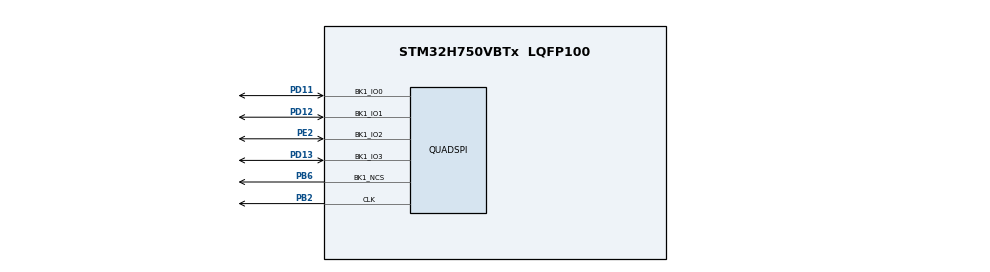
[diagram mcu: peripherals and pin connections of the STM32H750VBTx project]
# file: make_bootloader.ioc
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CORTEX_M7.default_mode_Activation=1
Mcu.Family=STM32H7
Mcu.Name=STM32H750VBTx
Mcu.Package=LQFP100
NVIC.PriorityGroup=NVIC_PRIORITYGROUP_4
PB2.GPIO_Speed=GPIO_SPEED_FREQ_VERY_HIGH
PB2.Mode=Single Bank 1
PB2.Signal=QUADSPI_CLK
PB6.GPIO_Speed=GPIO_SPEED_FREQ_VERY_HIGH
PB6.Mode=Single Bank 1
PB6.Signal=QUADSPI_BK1_NCS
PD11.GPIO_Speed=GPIO_SPEED_FREQ_VERY_HIGH
PD11.Mode=Single Bank 1
PD11.Signal=QUADSPI_BK1_IO0
PD12.GPIO_Speed=GPIO_SPEED_FREQ_VERY_HIGH
PD12.Mode=Single Bank 1
PD12.Signal=QUADSPI_BK1_IO1
PD13.GPIO_Speed=GPIO_SPEED_FREQ_VERY_HIGH
PD13.Mode=Single Bank 1
PD13.Signal=QUADSPI_BK1_IO3
PE2.GPIO_Speed=GPIO_SPEED_FREQ_VERY_HIGH
PE2.Mode=Single Bank 1
PE2.Signal=QUADSPI_BK1_IO2
PH0-OSC_IN\ (PH0).Mode=HSE-External-Oscillator
PH0-OSC_IN\ (PH0).Signal=RCC_OSC_IN
PH1-OSC_OUT\ (PH1).Mode=HSE-External-Oscillator
PH1-OSC_OUT\ (PH1).Signal=RCC_OSC_OUT
ProjectManager.HeapSize=0x200
ProjectManager.StackSize=0x400
ProjectManager.TargetToolchain=Makefile
RCC.ADCFreq_Value=200000000
RCC.APB1Freq_Value=120000000
RCC.APB2Freq_Value=120000000
RCC.APB3Freq_Value=120000000
RCC.APB4Freq_Value=120000000
RCC.CortexFreq_Value=480000000
RCC.D1PPRE=RCC_APB3_DIV2
RCC.D2PPRE1=RCC_APB1_DIV2
RCC.D2PPRE2=RCC_APB2_DIV2
RCC.D3PPRE=RCC_APB4_DIV2
RCC.DIVM1=5
RCC.DIVM2=8
RCC.DIVM3=5
RCC.DIVN1=192
RCC.DIVN2=128
RCC.DIVN3=128
RCC.HCLKFreq_Value=240000000
RCC.HPRE=RCC_HCLK_DIV2
RCC.PLLSourceVirtual=RCC_PLLSOURCE_HSE
RCC.SYSCLKFreq_VALUE=480000000
RCC.SYSCLKSource=RCC_SYSCLKSOURCE_PLLCLK
RCC.USBFreq_Value=480000000
board=custom

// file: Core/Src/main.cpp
/* USER CODE BEGIN Header */
/**
  ******************************************************************************
  * @file           : main.c
  * @brief          : Main program body
  ******************************************************************************
  * @attention
  *
  * Copyright (c) 2022 STMicroelectronics.
  * All rights reserved.
  *
  * This software is licensed under terms that can be found in the LICENSE file
  * in the root directory of this software component.
  * If no LICENSE file comes with this software, it is provided AS-IS.
  *
  ******************************************************************************
  */
/* USER CODE END Header */
#include "main.h"
#include "w25q64.h"

QSPI_HandleTypeDef hqspi;

void SystemClock_Config(void);
static void MPU_Config(void);
static void MX_GPIO_Init(void);
static void MX_QUADSPI_Init(void);

/* USER CODE BEGIN 0 */
#define VECT_TAB_OFFSET      0x00000000UL
#define APPLICATION_ADDRESS  0x90000000UL

typedef  void (*pFunction)(void);
pFunction JumpToApplication;
Flash_T w25q64 = Flash_T();

/* USER CODE END 0 */

int main(void)
{

	/* MPU Configuration--------------------------------------------------------*/
	MPU_Config();

	/* MCU Configuration--------------------------------------------------------*/

	/* Reset of all peripherals, Initializes the Flash interface and the Systick. */
	HAL_Init();

	/* Configure the system clock */
	SystemClock_Config();

	/* Initialize all configured peripherals */
	MX_GPIO_Init();
	MX_QUADSPI_Init();
	/* USER CODE BEGIN 2 */
	w25q64.init();
	HAL_MPU_Disable();
	// SCB_DisableDCache();
	w25q64.memory_map();

	SysTick->CTRL = 0;
	SysTick->LOAD = 0;
	SysTick->VAL = 0;
	for(uint8_t i = 0; i < 8; i++)
	{
		NVIC->ICER[i]=0xFFFFFFFF;
		NVIC->ICPR[i]=0xFFFFFFFF;
	}
	__set_CONTROL(0);
	__disable_irq();
	__set_PRIMASK(1);
	HAL_GPIO_DeInit(GPIOE, GPIO_PIN_3);

	JumpToApplication = (pFunction) (*(__IO uint32_t*)(APPLICATION_ADDRESS + 4));
	__set_MSP(*(__IO uint32_t*) APPLICATION_ADDRESS);
	JumpToApplication();

	/* USER CODE END 2 */

	/* Infinite loop */
	while (1)
	{

		/* USER CODE BEGIN 3 */
		HAL_Delay(500);
		HAL_GPIO_TogglePin(GPIOE, GPIO_PIN_3);
	}
  	/* USER CODE END 3 */
}

void SystemClock_Config(void)
{
  RCC_OscInitTypeDef RCC_OscInitStruct = {0};
  RCC_ClkInitTypeDef RCC_ClkInitStruct = {0};

  /** Supply configuration update enable
  */
  HAL_PWREx_ConfigSupply(PWR_LDO_SUPPLY);

  /** Configure the main internal regulator output voltage
  */
  __HAL_PWR_VOLTAGESCALING_CONFIG(PWR_REGULATOR_VOLTAGE_SCALE0);

  while(!__HAL_PWR_GET_FLAG(PWR_FLAG_VOSRDY)) {}

  /** Initializes the RCC Oscillators according to the specified parameters
  * in the RCC_OscInitTypeDef structure.
  */
  RCC_OscInitStruct.OscillatorType = RCC_OSCILLATORTYPE_HSE;
  RCC_OscInitStruct.HSEState = RCC_HSE_ON;
  RCC_OscInitStruct.PLL.PLLState = RCC_PLL_ON;
  RCC_OscInitStruct.PLL.PLLSource = RCC_PLLSOURCE_HSE;
  RCC_OscInitStruct.PLL.PLLM = 5;
  RCC_OscInitStruct.PLL.PLLN = 192;
  RCC_OscInitStruct.PLL.PLLP = 2;
  RCC_OscInitStruct.PLL.PLLQ = 2;
  RCC_OscInitStruct.PLL.PLLR = 2;
  RCC_OscInitStruct.PLL.PLLRGE = RCC_PLL1VCIRANGE_2;
  RCC_OscInitStruct.PLL.PLLVCOSEL = RCC_PLL1VCOWIDE;
  RCC_OscInitStruct.PLL.PLLFRACN = 0;
  if (HAL_RCC_OscConfig(&RCC_OscInitStruct) != HAL_OK)
  {
	Error_Handler();
  }

  /** Initializes the CPU, AHB and APB buses clocks
  */
  RCC_ClkInitStruct.ClockType = RCC_CLOCKTYPE_HCLK|RCC_CLOCKTYPE_SYSCLK
							  |RCC_CLOCKTYPE_PCLK1|RCC_CLOCKTYPE_PCLK2
							  |RCC_CLOCKTYPE_D3PCLK1|RCC_CLOCKTYPE_D1PCLK1;
  RCC_ClkInitStruct.SYSCLKSource = RCC_SYSCLKSOURCE_PLLCLK;
  RCC_ClkInitStruct.SYSCLKDivider = RCC_SYSCLK_DIV1;
  RCC_ClkInitStruct.AHBCLKDivider = RCC_HCLK_DIV2;
  RCC_ClkInitStruct.APB3CLKDivider = RCC_APB3_DIV2;
  RCC_ClkInitStruct.APB1CLKDivider = RCC_APB1_DIV2;
  RCC_ClkInitStruct.APB2CLKDivider = RCC_APB2_DIV2;
  RCC_ClkInitStruct.APB4CLKDivider = RCC_APB4_DIV2;

  if (HAL_RCC_ClockConfig(&RCC_ClkInitStruct, FLASH_LATENCY_4) != HAL_OK)
  {
	Error_Handler();
  }
}

static void MX_QUADSPI_Init(void)
{

  /* QUADSPI parameter configuration*/
  hqspi.Instance = QUADSPI;
  hqspi.Init.ClockPrescaler = 2;
  hqspi.Init.FifoThreshold = 4;
  hqspi.Init.SampleShifting = QSPI_SAMPLE_SHIFTING_HALFCYCLE;
  hqspi.Init.FlashSize = POSITION_VAL(0X800000)-1;
  hqspi.Init.ChipSelectHighTime = QSPI_CS_HIGH_TIME_5_CYCLE;
  hqspi.Init.ClockMode = QSPI_CLOCK_MODE_0;
  hqspi.Init.FlashID = QSPI_FLASH_ID_1;
  hqspi.Init.DualFlash = QSPI_DUALFLASH_DISABLE;
  if (HAL_QSPI_Init(&hqspi) != HAL_OK)
  {
	Error_Handler();
  }
  /* USER CODE BEGIN QUADSPI_Init 2 */
//   HAL_QSPI_MspInit(&hqspi);
  /* USER CODE END QUADSPI_Init 2 */

}

static void MX_GPIO_Init(void)
{
  GPIO_InitTypeDef GPIO_InitStruct = {0};

  /* GPIO Ports Clock Enable */
  __HAL_RCC_GPIOE_CLK_ENABLE();
  __HAL_RCC_GPIOH_CLK_ENABLE();
  __HAL_RCC_GPIOA_CLK_ENABLE();
  __HAL_RCC_GPIOB_CLK_ENABLE();
  __HAL_RCC_GPIOD_CLK_ENABLE();
  /*Configure GPIO pin Output Level */
  HAL_GPIO_WritePin(GPIOE, GPIO_PIN_3, GPIO_PIN_RESET);

  /*Configure GPIO pin : PE3 */
  GPIO_InitStruct.Pin = GPIO_PIN_3;
  GPIO_InitStruct.Mode = GPIO_MODE_OUTPUT_PP;
  GPIO_InitStruct.Pull = GPIO_NOPULL;
  GPIO_InitStruct.Speed = GPIO_SPEED_FREQ_LOW;
  HAL_GPIO_Init(GPIOE, &GPIO_InitStruct);
}

/* MPU Configuration */

void MPU_Config(void)
{
  MPU_Region_InitTypeDef MPU_InitStruct = {0};

  /* Disables the MPU */
  HAL_MPU_Disable();

  /** Initializes and configures the Region and the memory to be protected
  */
  MPU_InitStruct.Enable = MPU_REGION_ENABLE;
  MPU_InitStruct.Number = MPU_REGION_NUMBER0;
  MPU_InitStruct.BaseAddress = 0x0;
  MPU_InitStruct.Size = MPU_REGION_SIZE_4GB;
  MPU_InitStruct.SubRegionDisable = 0x87;
  MPU_InitStruct.TypeExtField = MPU_TEX_LEVEL0;
  MPU_InitStruct.AccessPermission = MPU_REGION_NO_ACCESS;
  MPU_InitStruct.DisableExec = MPU_INSTRUCTION_ACCESS_DISABLE;
  MPU_InitStruct.IsShareable = MPU_ACCESS_SHAREABLE;
  MPU_InitStruct.IsCacheable = MPU_ACCESS_NOT_CACHEABLE;
  MPU_InitStruct.IsBufferable = MPU_ACCESS_NOT_BUFFERABLE;

  HAL_MPU_ConfigRegion(&MPU_InitStruct);
  /* Enables the MPU */
  HAL_MPU_Enable(MPU_PRIVILEGED_DEFAULT);

}

void Error_Handler(void)
{
  __disable_irq();
  while (1)
  {
  }
}
void SVC_Handler(void)
{
	__set_CONTROL( __get_CONTROL( ) & ~CONTROL_nPRIV_Msk ) ;
}
